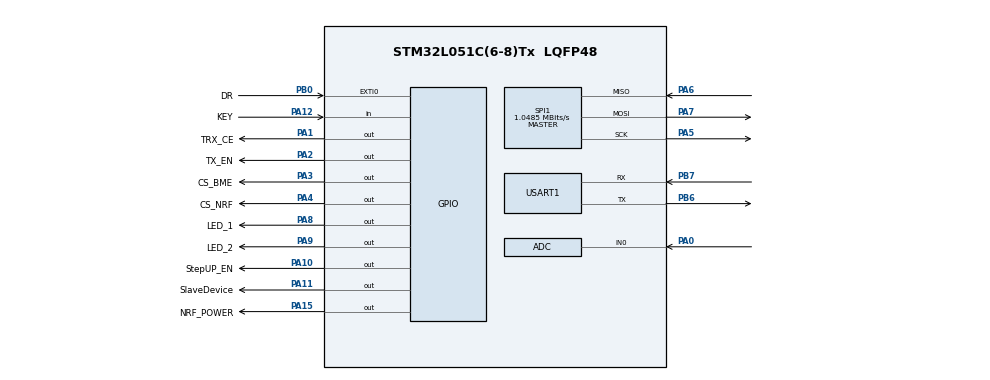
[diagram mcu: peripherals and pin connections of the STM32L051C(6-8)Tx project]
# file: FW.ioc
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Dma.ADC.0.Direction=DMA_PERIPH_TO_MEMORY
Dma.ADC.0.Instance=DMA1_Channel1
Dma.ADC.0.MemDataAlignment=DMA_MDATAALIGN_HALFWORD
Dma.ADC.0.MemInc=DMA_MINC_ENABLE
Dma.ADC.0.Mode=DMA_NORMAL
Dma.ADC.0.PeriphDataAlignment=DMA_PDATAALIGN_HALFWORD
Dma.ADC.0.PeriphInc=DMA_PINC_DISABLE
Dma.ADC.0.Priority=DMA_PRIORITY_LOW
Dma.Request0=ADC
Mcu.Family=STM32L0
Mcu.Name=STM32L051C(6-8)Tx
Mcu.Package=LQFP48
NVIC.DMA1_Channel1_IRQn=true\:0\:0\:false\:false\:true\:false\:true
NVIC.EXTI0_1_IRQn=true\:0\:0\:false\:false\:true\:true\:true
NVIC.RTC_IRQn=true\:0\:0\:false\:false\:true\:true\:true
PA0.Mode=IN0
PA0.Signal=ADC_IN0
PA1.GPIO_Label=TRX_CE
PA1.Signal=GPIO_Output
PA10.GPIO_Label=StepUP_EN
PA10.Signal=GPIO_Output
PA11.GPIO_Label=SlaveDevice
PA11.Signal=GPIO_Output
PA12.GPIO_Label=KEY
PA12.Signal=GPIO_Input
PA13.Mode=Serial_Wire
PA13.Signal=SYS_SWDIO
PA14.Mode=Serial_Wire
PA14.Signal=SYS_SWCLK
PA15.GPIO_Label=NRF_POWER
PA15.Signal=GPIO_Output
PA2.GPIO_Label=TX_EN
PA2.Signal=GPIO_Output
PA3.GPIO_Label=CS_BME
PA3.Signal=GPIO_Output
PA4.GPIO_Label=CS_NRF
PA4.Signal=GPIO_Output
PA5.Mode=Full_Duplex_Master
PA5.Signal=SPI1_SCK
PA6.Mode=Full_Duplex_Master
PA6.Signal=SPI1_MISO
PA7.Mode=Full_Duplex_Master
PA7.Signal=SPI1_MOSI
PA8.GPIO_Label=LED_1
PA8.Signal=GPIO_Output
PA9.GPIO_Label=LED_2
PA9.Signal=GPIO_Output
PB0.GPIO_Label=DR
PB0.Signal=GPXTI0
PB6.Mode=Asynchronous
PB6.Signal=USART1_TX
PB7.Mode=Asynchronous
PB7.Signal=USART1_RX
ProjectManager.HeapSize=0x200
ProjectManager.StackSize=0x400
ProjectManager.TargetToolchain=Makefile
RCC.AHBFreq_Value=2097000
RCC.APB1Freq_Value=2097000
RCC.APB1TimFreq_Value=2097000
RCC.APB2Freq_Value=2097000
RCC.APB2TimFreq_Value=2097000
RCC.HSE_VALUE=8000000
RCC.HSI16_VALUE=16000000
RCC.HSI_VALUE=16000000
RCC.LSE_VALUE=32768
RCC.MSI_VALUE=2097000
RCC.SYSCLKFreq_VALUE=2097000
RCC.VCOOutputFreq_Value=48000000
RTC.WakeUpClock-WakeUp=RTC_WAKEUPCLOCK_CK_SPRE_16BITS
RTC.WakeUpCounter-WakeUp=300
SPI1.CalculateBaudRate=1.0485 MBits/s
SPI1.Direction=SPI_DIRECTION_2LINES
SPI1.Mode=SPI_MODE_MASTER
SPI1.VirtualType=VM_MASTER
USART1.VirtualMode-Asynchronous=VM_ASYNC
VP_ADC_Vref_Input.Mode=IN-Vrefint
VP_RTC_VS_RTC_Activate.Mode=RTC_Enabled
VP_RTC_VS_RTC_WakeUp_intern.Mode=WakeUp
board=custom

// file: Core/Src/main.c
/* USER CODE BEGIN Header */
/**
  ******************************************************************************
  * @file           : main.c
  * @brief          : Main program body
  ******************************************************************************
  * @attention
  *
  * <h2><center>&copy; Copyright (c) 2020 STMicroelectronics.
  * All rights reserved.</center></h2>
  *
  * This software component is licensed by ST under BSD 3-Clause license,
  * the "License"; You may not use this file except in compliance with the
  * License. You may obtain a copy of the License at:
  *                        opensource.org/licenses/BSD-3-Clause
  *
  ******************************************************************************
  */
/* USER CODE END Header */
#include "main.h"
#include "adc.h"
#include "dma.h"
#include "rtc.h"
#include "spi.h"
#include "usart.h"
#include "gpio.h"
#include "stm32l051xx.h"

/* USER CODE BEGIN Includes */
#include "bme280.h"
#include "nrf905.h"

/* USER CODE END Includes */

/* USER CODE BEGIN PTD */

Packet_send P;

/* USER CODE END PTD */

/* USER CODE BEGIN PD */
struct bme280_dev dev_bme = {0};

/* USER CODE END PD */

void SystemClock_Config(void);

int main(void)
{

  /* MCU Configuration--------------------------------------------------------*/

  /* Reset of all peripherals, Initializes the Flash interface and the Systick. */

  LL_APB2_GRP1_EnableClock(LL_APB2_GRP1_PERIPH_SYSCFG);
  LL_APB1_GRP1_EnableClock(LL_APB1_GRP1_PERIPH_PWR);

  /* System interrupt init*/

  /* Configure the system clock */
  SystemClock_Config();

  /* Initialize all configured peripherals */
  MX_GPIO_Init();
  MX_DMA_Init();
  MX_ADC_Init();
  MX_RTC_Init();
  MX_SPI1_Init();
  MX_USART1_UART_Init();

  /* Infinite loop */
  while (1)
  {

  }
}

void SystemClock_Config(void)
{
  LL_FLASH_SetLatency(LL_FLASH_LATENCY_0);
  while(LL_FLASH_GetLatency()!= LL_FLASH_LATENCY_0)
  {
  }
  LL_PWR_SetRegulVoltageScaling(LL_PWR_REGU_VOLTAGE_SCALE1);
  LL_RCC_LSI_Enable();

   /* Wait till LSI is ready */
  while(LL_RCC_LSI_IsReady() != 1)
  {

  }
  LL_RCC_MSI_Enable();

   /* Wait till MSI is ready */
  while(LL_RCC_MSI_IsReady() != 1)
  {

  }
  LL_RCC_MSI_SetRange(LL_RCC_MSIRANGE_5);
  LL_RCC_MSI_SetCalibTrimming(0);
  LL_PWR_EnableBkUpAccess();
  if(LL_RCC_GetRTCClockSource() != LL_RCC_RTC_CLKSOURCE_LSI)
  {
    LL_RCC_ForceBackupDomainReset();
    LL_RCC_ReleaseBackupDomainReset();
    LL_RCC_SetRTCClockSource(LL_RCC_RTC_CLKSOURCE_LSI);
  }
  LL_RCC_EnableRTC();
  LL_RCC_SetAHBPrescaler(LL_RCC_SYSCLK_DIV_1);
  LL_RCC_SetAPB1Prescaler(LL_RCC_APB1_DIV_1);
  LL_RCC_SetAPB2Prescaler(LL_RCC_APB2_DIV_1);
  LL_RCC_SetSysClkSource(LL_RCC_SYS_CLKSOURCE_MSI);

   /* Wait till System clock is ready */
  while(LL_RCC_GetSysClkSource() != LL_RCC_SYS_CLKSOURCE_STATUS_MSI)
  {

  }

  LL_Init1msTick(2097000);

  LL_SetSystemCoreClock(2097000);
 // LL_RCC_SetUSARTClockSource(LL_RCC_USART1_CLKSOURCE_PCLK1);
}

/* USER CODE BEGIN 4 */
/*

*/
uint16_t flash_read(uint32_t address)
{
    return (*(__IO uint16_t*) address);
}
/* USER CODE END 4 */

void Error_Handler(void)
{
}

/************************ (C) COPYRIGHT STMicroelectronics *****END OF FILE****/
